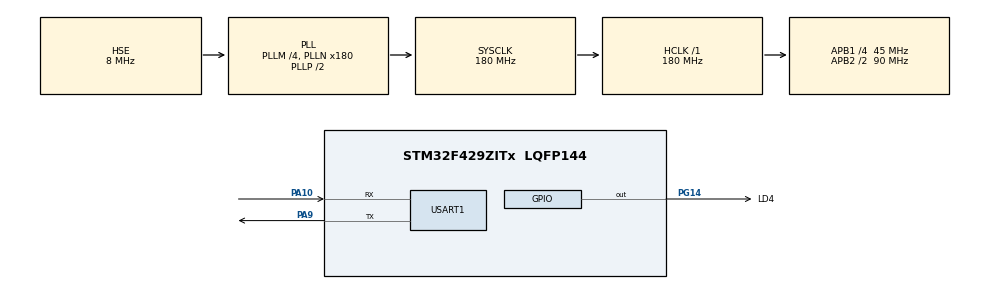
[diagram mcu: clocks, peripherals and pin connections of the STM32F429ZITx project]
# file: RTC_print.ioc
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Mcu.Family=STM32F4
Mcu.Name=STM32F429ZITx
Mcu.Package=LQFP144
NVIC.PriorityGroup=NVIC_PRIORITYGROUP_4
PA10.Mode=Asynchronous
PA10.Signal=USART1_RX
PA9.Mode=Asynchronous
PA9.Signal=USART1_TX
PG14.GPIO_Label=LD4
PG14.GPIO_Speed=GPIO_SPEED_FREQ_HIGH
PG14.Signal=GPIO_Output
PH0/OSC_IN.Mode=HSE-External-Oscillator
PH0/OSC_IN.Signal=RCC_OSC_IN
PH1/OSC_OUT.Mode=HSE-External-Oscillator
PH1/OSC_OUT.Signal=RCC_OSC_OUT
ProjectManager.HeapSize=0x200
ProjectManager.StackSize=0x400
ProjectManager.TargetToolchain=STM32CubeIDE
RCC.48MHZClocksFreq_Value=90000000
RCC.AHBFreq_Value=180000000
RCC.APB1CLKDivider=RCC_HCLK_DIV4
RCC.APB1Freq_Value=45000000
RCC.APB1TimFreq_Value=90000000
RCC.APB2CLKDivider=RCC_HCLK_DIV2
RCC.APB2Freq_Value=90000000
RCC.APB2TimFreq_Value=180000000
RCC.CortexFreq_Value=180000000
RCC.HCLKFreq_Value=180000000
RCC.HSE_VALUE=8000000
RCC.HSI_VALUE=16000000
RCC.LSE_VALUE=32768
RCC.PLLM=4
RCC.PLLN=180
RCC.PLLSourceVirtual=RCC_PLLSOURCE_HSE
RCC.RCC_RTC_Clock_SourceVirtual=RCC_RTCCLKSOURCE_HSE_DIV8
RCC.RCC_RTC_Clock_Source_FROM_HSE=RCC_RTCCLKSOURCE_HSE_DIV8
RCC.SYSCLKFreq_VALUE=180000000
RCC.SYSCLKSource=RCC_SYSCLKSOURCE_PLLCLK
RCC.VCOOutputFreq_Value=360000000
RTC.AsynchPrediv=124
RTC.Date=4
RTC.Format=RTC_FORMAT_BIN
RTC.HourFormat=RTC_HOURFORMAT_24
RTC.Hours=12
RTC.Month=RTC_MONTH_DECEMBER
RTC.SynchPrediv=7999
RTC.WeekDay=RTC_WEEKDAY_SUNDAY
RTC.Year=22
USART1.VirtualMode=VM_ASYNC
VP_RTC_VS_RTC_Activate.Mode=RTC_Enabled
VP_RTC_VS_RTC_Calendar.Mode=RTC_Calendar
board=custom

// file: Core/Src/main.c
/* USER CODE BEGIN Header */
/**
 ******************************************************************************
 * @file           : main.c
 * @brief          : Main program body
 ******************************************************************************
 * @attention
 *
 * Copyright (c) 2022 STMicroelectronics.
 * All rights reserved.
 *
 * This software is licensed under terms that can be found in the LICENSE file
 * in the root directory of this software component.
 * If no LICENSE file comes with this software, it is provided AS-IS.
 *
 ******************************************************************************
 */
/* USER CODE END Header */
#include "main.h"
#include "stdio.h"

RTC_HandleTypeDef hrtc;

UART_HandleTypeDef huart1;

/*
 int _write(int file, char* str, int length)
 {
 HAL_UART_Transmit(&huart1, str, length, 10);

 return length;
 }
 */

int __io_putchar(int ch) {
	(void) HAL_UART_Transmit(&huart1, (uint8_t*) &ch, 1, 100);
	return ch;
}

void SystemClock_Config(void);
static void MX_GPIO_Init(void);
static void MX_RTC_Init(void);
static void MX_USART1_UART_Init(void);

int main(void) {

	/* MCU Configuration--------------------------------------------------------*/

	/* Reset of all peripherals, Initializes the Flash interface and the Systick. */
	HAL_Init();

	/* Configure the system clock */
	SystemClock_Config();

	/* Initialize all configured peripherals */
	MX_GPIO_Init();
	MX_RTC_Init();
	MX_USART1_UART_Init();
	/* USER CODE BEGIN 2 */

	RTC_TimeTypeDef sTime;
	RTC_DateTypeDef sDate;

	HAL_RTC_GetTime(&hrtc, &sTime, RTC_FORMAT_BIN);
	//tick_Seconds=sTime.Seconds;

	/* USER CODE END 2 */
	//char uart_buf;
	/* Infinite loop */
	/* USER CODE BEGIN WHILE */
	while (1) {
		HAL_RTC_GetTime(&hrtc, &sTime, RTC_FORMAT_BIN);
		HAL_RTC_GetDate(&hrtc, &sDate, RTC_FORMAT_BIN);

		HAL_GPIO_TogglePin(GPIOG, LD4_Pin);
		//printf("LED ON\r\n");
		printf("%04d-%02d-%02d -- %02d:%02d:%02d\r\n", sDate.Year + 2000,
				sDate.Month, sDate.Date, sTime.Hours, sTime.Minutes,
				sTime.Seconds);
		HAL_Delay(1000);

	}
}

void SystemClock_Config(void) {
	RCC_OscInitTypeDef RCC_OscInitStruct = { 0 };
	RCC_ClkInitTypeDef RCC_ClkInitStruct = { 0 };

	/** Configure the main internal regulator output voltage
	 */
	__HAL_RCC_PWR_CLK_ENABLE();
	__HAL_PWR_VOLTAGESCALING_CONFIG(PWR_REGULATOR_VOLTAGE_SCALE1);

	/** Initializes the RCC Oscillators according to the specified parameters
	 * in the RCC_OscInitTypeDef structure.
	 */
	RCC_OscInitStruct.OscillatorType = RCC_OSCILLATORTYPE_HSE;
	RCC_OscInitStruct.HSEState = RCC_HSE_ON;
	RCC_OscInitStruct.PLL.PLLState = RCC_PLL_ON;
	RCC_OscInitStruct.PLL.PLLSource = RCC_PLLSOURCE_HSE;
	RCC_OscInitStruct.PLL.PLLM = 4;
	RCC_OscInitStruct.PLL.PLLN = 180;
	RCC_OscInitStruct.PLL.PLLP = RCC_PLLP_DIV2;
	RCC_OscInitStruct.PLL.PLLQ = 4;
	if (HAL_RCC_OscConfig(&RCC_OscInitStruct) != HAL_OK) {
		Error_Handler();
	}

	/** Activate the Over-Drive mode
	 */
	if (HAL_PWREx_EnableOverDrive() != HAL_OK) {
		Error_Handler();
	}

	/** Initializes the CPU, AHB and APB buses clocks
	 */
	RCC_ClkInitStruct.ClockType = RCC_CLOCKTYPE_HCLK | RCC_CLOCKTYPE_SYSCLK
			| RCC_CLOCKTYPE_PCLK1 | RCC_CLOCKTYPE_PCLK2;
	RCC_ClkInitStruct.SYSCLKSource = RCC_SYSCLKSOURCE_PLLCLK;
	RCC_ClkInitStruct.AHBCLKDivider = RCC_SYSCLK_DIV1;
	RCC_ClkInitStruct.APB1CLKDivider = RCC_HCLK_DIV4;
	RCC_ClkInitStruct.APB2CLKDivider = RCC_HCLK_DIV2;

	if (HAL_RCC_ClockConfig(&RCC_ClkInitStruct, FLASH_LATENCY_5) != HAL_OK) {
		Error_Handler();
	}
}

static void MX_RTC_Init(void) {

	RTC_TimeTypeDef sTime = { 0 };
	RTC_DateTypeDef sDate = { 0 };

	/** Initialize RTC Only
	 */
	hrtc.Instance = RTC;
	hrtc.Init.HourFormat = RTC_HOURFORMAT_24;
	hrtc.Init.AsynchPrediv = 124;
	hrtc.Init.SynchPrediv = 7999;
	hrtc.Init.OutPut = RTC_OUTPUT_DISABLE;
	hrtc.Init.OutPutPolarity = RTC_OUTPUT_POLARITY_HIGH;
	hrtc.Init.OutPutType = RTC_OUTPUT_TYPE_OPENDRAIN;
	if (HAL_RTC_Init(&hrtc) != HAL_OK) {
		Error_Handler();
	}

	/** Initialize RTC and set the Time and Date
	 */
	sTime.Hours = 6;
	sTime.Minutes = 22;
	sTime.Seconds = 0;
	sTime.DayLightSaving = RTC_DAYLIGHTSAVING_NONE;
	sTime.StoreOperation = RTC_STOREOPERATION_RESET;
	if (HAL_RTC_SetTime(&hrtc, &sTime, RTC_FORMAT_BIN) != HAL_OK) {
		Error_Handler();
	}
	sDate.WeekDay = RTC_WEEKDAY_THURSDAY;
	sDate.Month = RTC_MONTH_FEBRUARY;
	sDate.Date = 5;
	sDate.Year = 23;

	if (HAL_RTC_SetDate(&hrtc, &sDate, RTC_FORMAT_BIN) != HAL_OK) {
		Error_Handler();
	}

}

static void MX_USART1_UART_Init(void) {

	huart1.Instance = USART1;
	huart1.Init.BaudRate = 115200;
	huart1.Init.WordLength = UART_WORDLENGTH_8B;
	huart1.Init.StopBits = UART_STOPBITS_1;
	huart1.Init.Parity = UART_PARITY_NONE;
	huart1.Init.Mode = UART_MODE_TX_RX;
	huart1.Init.HwFlowCtl = UART_HWCONTROL_NONE;
	huart1.Init.OverSampling = UART_OVERSAMPLING_16;
	if (HAL_UART_Init(&huart1) != HAL_OK) {
		Error_Handler();
	}

}

static void MX_GPIO_Init(void) {
	GPIO_InitTypeDef GPIO_InitStruct = { 0 };

	/* GPIO Ports Clock Enable */
	__HAL_RCC_GPIOH_CLK_ENABLE();
	__HAL_RCC_GPIOA_CLK_ENABLE();
	__HAL_RCC_GPIOG_CLK_ENABLE();

	/*Configure GPIO pin Output Level */
	HAL_GPIO_WritePin(LD4_GPIO_Port, LD4_Pin, GPIO_PIN_RESET);

	/*Configure GPIO pin : LD4_Pin */
	GPIO_InitStruct.Pin = LD4_Pin;
	GPIO_InitStruct.Mode = GPIO_MODE_OUTPUT_PP;
	GPIO_InitStruct.Pull = GPIO_NOPULL;
	GPIO_InitStruct.Speed = GPIO_SPEED_FREQ_HIGH;
	HAL_GPIO_Init(LD4_GPIO_Port, &GPIO_InitStruct);

}

void Error_Handler(void) {
	__disable_irq();
	while (1) {
	}
}
